# psc3_p8_ppca register map
Vendor: Infineon Technologies; Series: PSC3_P8; File version: 1.0
CPU: CM33 r0p1, little endian, MPU, FPU, DSP, VTOR, 3 interrupt priority bits, 143 interrupts
Registers are 32-bit, read-write, reset 0x0 unless marked. A register's access mark holds for its fields unless they carry their own. Offsets are from the block's base; [hi:lo] are bit positions; lines under a group give offsets from that group; {n}, {i} and the like mark numbered series.

## PPCA_EPU
Base 0x43004000
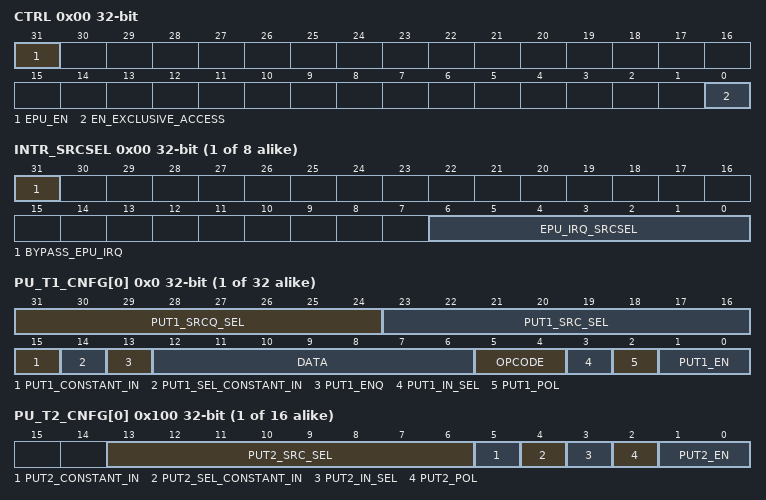
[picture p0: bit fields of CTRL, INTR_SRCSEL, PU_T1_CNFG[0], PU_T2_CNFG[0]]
0x00 CTRL
  [31] EPU_EN — PPCA_EPU peripheral enable: 0 = disable (only mmio CTRL registers is accessible) 1 = enable (all AHB registers in the PPCA_EPU are accessible)
  [0] EN_EXCLUSIVE_ACCESS — Enable exclusive access to the EPU resources based on the provided resources allocation configuration: 0 = disable (all EPU resources can be accessed by both CPU0 & CPU1, i.e. the configuration registers are ignored) 1 = enable (CPU0 or CPU1 can access only its own resources, as specified by the configuration registers)
{0x100+0x20*i} EPU_IRQ[{i}] (i=0..7) group
  0x00 INTR_SRCSEL — Interrupt Source Selection Register
    [31] BYPASS_EPU_IRQ — Bypass EPU_IRQ formatter logic: 0 = Formatter is active 1 = Bypass Formatter
    [6:0] EPU_IRQ_SRCSEL — select one COMBO output as interrupt source
  0x10 INTR — Interrupt Request Register
    [0] EPU_INTR write-1-clears — Interrupt requests of EPU
  0x14 INTR_SET — Interrupt Set Request Register
    [0] EPU_INTR_SET write-1-sets — Write INTR_SET field with '1' to set corresponding INTR field. When read, this register reflects the interrupt request register. That is the INTR register.
  0x18 INTR_MASK — Interrupt Mask Register
    [0] EPU_INTR_MASK — Mask for corresponding field in INTR register.
  0x1C INTR_MASKED ro — Interrupt Masked Register
    [0] EPU_INTR_MASKED — Logical AND of corresponding interrupt request (INTR) and mask fields (INTR_MASK).
0x400 EPU group
  {0x0+4j} PU_T1_CNFG[{j}] (j=0..31)
    [31:24] PUT1_SRCQ_SEL — Qualifier Input Source Selection (max 256)
    [23:16] PUT1_SRC_SEL — Input Source Selection (max 256)
    [15] PUT1_CONSTANT_IN — Set the value of the CONSTANT_IN input signal 0 = CONSTANT_IN set to 0 1 = CONSTANT_IN set to 1
    [14] PUT1_SEL_CONSTANT_IN — Select CONSTANT_IN input to the PU units 1 = Select CONSTANT_IN 0 = Select EVIN
    [13] PUT1_ENQ — Enable/DisableQualifier input: 0 = Disable 1 = Enable
    [12:6] DATA
    [5:4] OPCODE — Select PU processing function: 0 = extracted rising edge and delay extracted pulse by configured DATA numbers of clock cycles (PU_TY1 7:0) 1 = Maks input signal after detection of first valid transition by configured DATA numbers of clock cycles 2 = Blank input signal after detection of first valid transition (rising and falling) by configured DATA numbers of clock cycles. 3 = Debounce input signal by configured DATA threshold express in number of clock cycles
    [3] PUT1_IN_SEL — Select Input of Processing Unit: 0 = Level signal (Output Polarity Inversion) 1 = Edge signal (Output of Edge Extractor which input is the Output of Polarity Inversion)
    [2] PUT1_POL — Enable/Disable Input Polarity inversion: 0 = Disable 1 = Enable
    [1:0] PUT1_EN — Enable/Disable and Bypass Configure of Processig Unit: 0 = Disable 1 = Enable Asynchronous Bypass 2 = Enable Synchronous Bypass 3 = Enable Processign Unit
  {0x100+4j} PU_T2_CNFG[{j}] (j=0..15)
    [13:6] PUT2_SRC_SEL — Input Source Selection (max 256)
    [5] PUT2_CONSTANT_IN — Set the value of the CONSTANT_IN input signal 0 = CONSTANT_IN set to 0 1 = CONSTANT_IN set to 1
    [4] PUT2_SEL_CONSTANT_IN — Select CONSTANT_IN input to the PU units 1 = Select CONSTANT_IN 0 = Select EVIN
    [3] PUT2_IN_SEL — Select Input of Processing Unit: 0 = Level signal (Output Polarity Inversion) 1 = Edge signal (Output of Edge Extractor which input is the Output of Polarity Inversion)
    [2] PUT2_POL — Enable/Disable Input Polarity inversion: 0 = Disable 1 = Enable
    [1:0] PUT2_EN — Enable/Disable and Bypass Configure of Processig Unit: 0 = Disable 1 = Enable Asynchronous Bypass 2 = Enable Synchronous Bypass 3 = Enable Synchronous Bypass
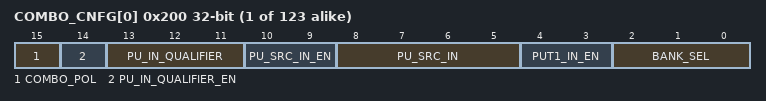
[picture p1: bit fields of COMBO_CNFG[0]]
  {0x200+4j} COMBO_CNFG[{j}] (j=0..122)
    [15] COMBO_POL — Enable/Disable Polarity inversion 0 = no output inversion 1 = invert output
    [14] PU_IN_QUALIFIER_EN — Enable/Disable qualifier 0 = disable 1 = enable
    [13:11] PU_IN_QUALIFIER — Select PU (= PU_T1_31:PU_T1_28, PU_T2_15:PU_T2_12) as qualifier for EVOUT: evout = evout_tmp & (pu_in_qualifier | ~pu_in_qualifier_en)
    [10:9] PU_SRC_IN_EN — Enable input signal: evout_tmp = pu_src_sel0 & pu_src_in_en[0] | pu_src_sel1 & pu_src_in_en[1]
    [8:5] PU_SRC_IN — Select {pu_src_sel0, pu_src_sel1} = {put1[16+i],put2[i]}, i=PU_SRC_SEL source input signal
    [4:3] PUT1_IN_EN — Enable input signal: evout_tmp = put1_sel[i] & put1_in_en[i]
    [2:0] BANK_SEL — Select input signals: put1_selected[i] = {put1[2*i],put1[2*i+1]}, i=BANK_SEL
  {0x400+4j} COMBO_FB_CNFG[{j}] (j=0..7)
    [6:0] COMBO_SRC_IN — Select COMBO output source signal. Signal is taken before PU_IN_QUALIFIER section
